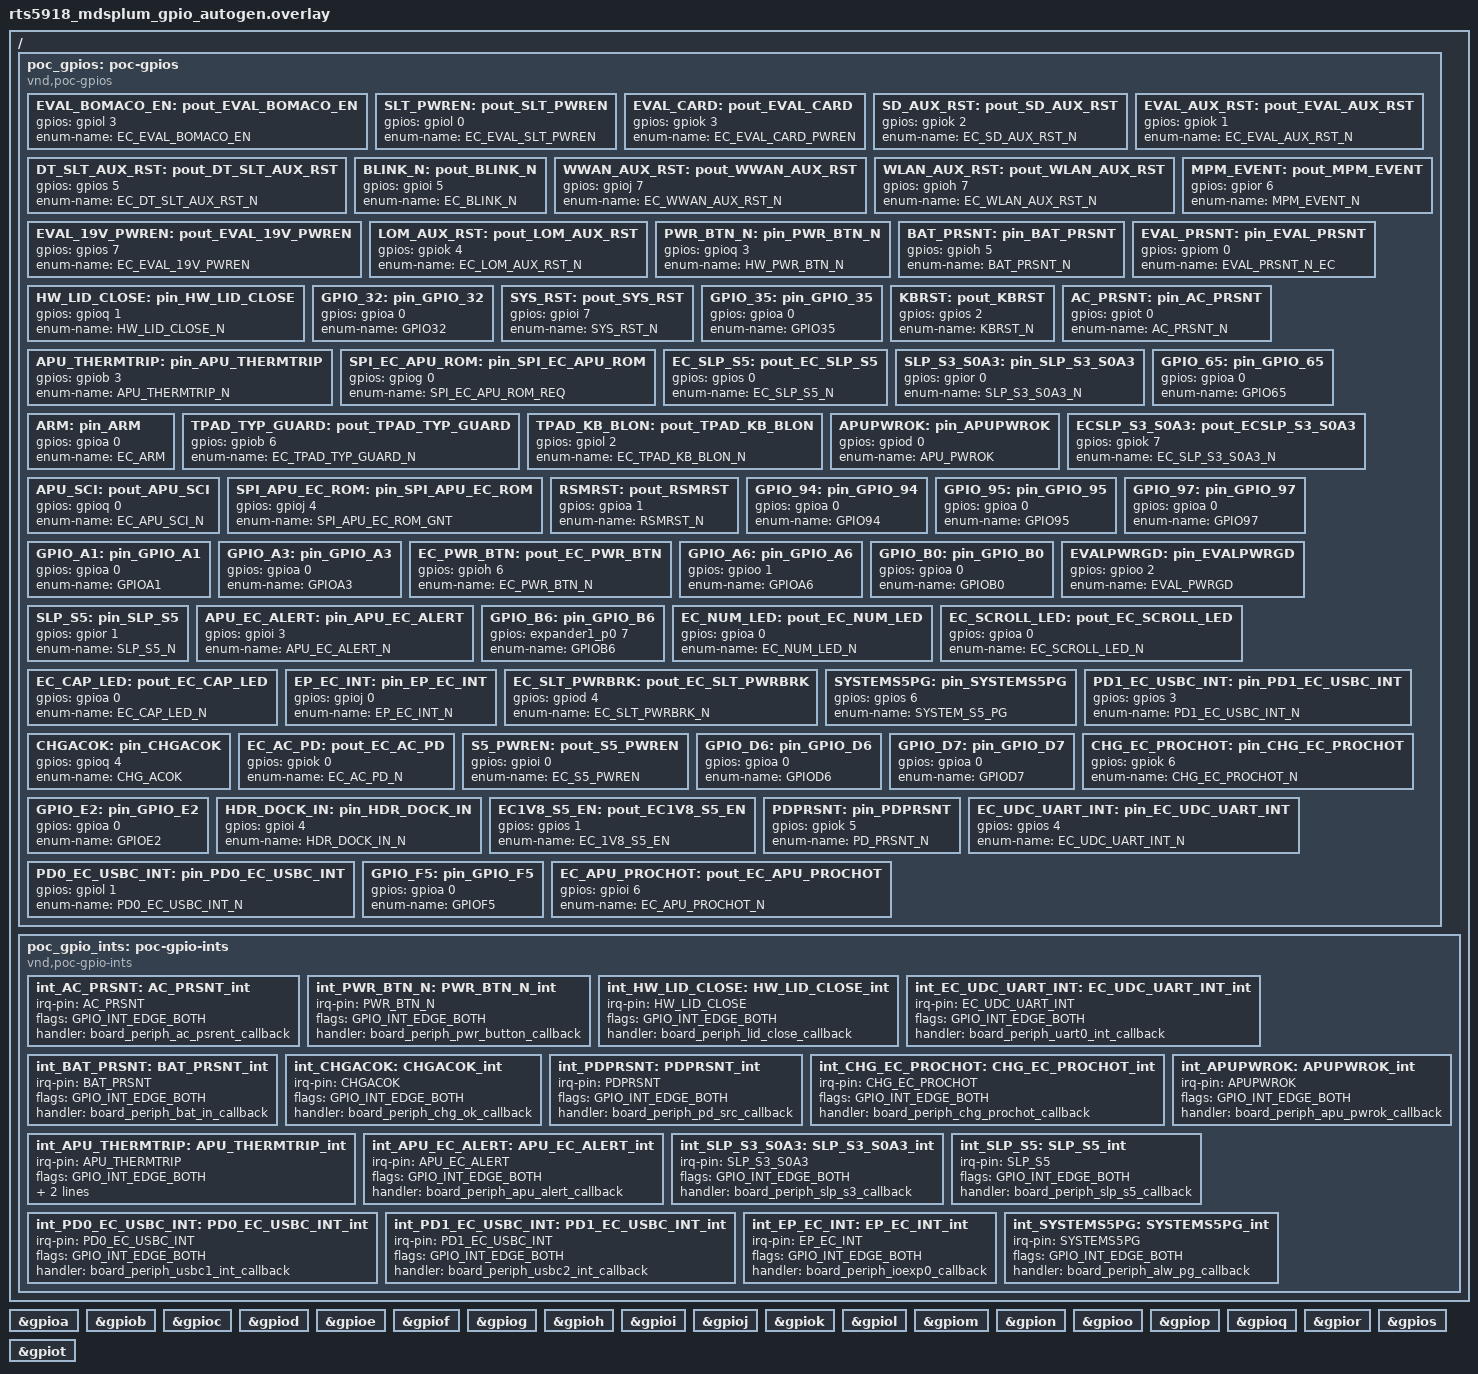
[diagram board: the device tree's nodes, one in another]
/*
 * SPDX-License-Identifier: Apache-2.0
 *
 * Copyright (c) 2026 Realtek Semiconductor Corporation, SIBG-SD7
 *
 * TODO(realtek-schematic): THIS FILE IS A BISON-LEGACY COPY.
 *
 * Every `gpios = <&gpio<bank> <pin> ...>` entry below was generated
 * from the Lenovo Bison schematic. The pad numbers are NOT correct
 * for AMD MDS Plum yet — they will need to be regenerated from a
 * Plum-specific BGA→net→pin spreadsheet once available.
 *
 * Until then the build still compiles because gpioa..gpiop are all
 * marked `status = "okay"`, but any runtime gpio_pin_set call against
 * an EC_GPIO_xx token will toggle the wrong physical pin. Do not
 * power up real Plum hardware with this overlay verbatim.
 *
 * Regeneration recipe (once Plum_pindef.xlsx exists):
 *   1. Copy boards/nuvoton/npcx4mnx_mdsplum/Plum_main.csv to
 *      gpio/plum_gpio.xlsx with columns: BGA, Net, RTS5918_Function.
 *   2. Run: python scripts/gen_poc_from_xlsx.py
 *      (port from lenovo_p/ecfw-zephyr/scripts/gen_poc_from_xlsx.py)
 *   3. Overwrite this file with the output.
 *
 * AUTO-GENERATED by scripts/gen_poc_from_xlsx.py from:
 *   ../gpio/GPIO_copy.dtsi   -- template: structure, order, labels, comments
 *   ../gpio/bison_gpio.xlsx  -- data: BGA_NET_CODE + rts5918_pin_function
 *                               joined on BGA -> (Code, Net, Function)
 *
 * Transformations applied vs. the source dtsi:
 *   * compatible renamed to the Realtek "vnd,poc-gpios" /
 *     "vnd,poc-gpio-ints" bindings.
 *   * &{/def-io-conf-list} pinmux block removed -- Realtek uses
 *     realtek/ec/rts5918-pinctrl.dtsi, wired up in rts5918_bison.dts.
 *   * eSPI VWire children rewritten: the Nuvoton-specific &msvw0x /
 *     &smvw0x phandles are replaced with &gpioa 0 because RTS5918 has
 *     no msvw/smvw devicetree nodes, but the GPIO_VWIRE flag is kept
 *     so the encoded enum value carries BIT(20) and IoPort.c (line
 *     ~441/584) routes IoSet/IoClr/IoGet calls via the eSPI VW
 *     dispatcher. Each entry in the xlsx `vwire_signals` sheet that
 *     the template doesn't already include is appended automatically.
 *   * `gpios = <&gpio<N> <pin> ...>` rewritten to
 *     `gpios = <&gpio<a..t> <pin%8> ...>` using linear GPIO# =
 *     bank*8+pin (verified from RTS5918.h IRQ comments).
 *   * Nuvoton flag tokens (GPIO_OUTPUT_HIGH / GPIO_OUTPUT_LOW /
 *     GPIO_DEFINE) preserved verbatim -- all are defined in
 *     include/dt-bindings/gpio_defines.h and expand to the expected
 *     bit pattern after the devicetree preprocessor runs.
 *   * GPIO_DEFINE stripped only when that row is falling through to a
 *     GPIO_UNDEFINE_PIN stub (the two are opposites).
 *   * Interrupt children with GPIO_INT_DISABLE flags dropped
 *     (Realtek binding does not accept the disabled variant).
 *   * Template rows without a real BGA mapping that are not eSPI
 *     vwire signals are emitted as GPIO_UNDEFINE_PIN stubs (encoded
 *     enum carries BIT(30) so middle/gpio/mdl_gpio_hub.c safety net
 *     returns -ENODEV at runtime). The PInGpio<NNN> generic-name family
 *     (PInGpio001 / PInGpio0H4 / PInGpioSBY01...) is the lone
 *     exception: it is dropped entirely; syspower.c
 *     IoPortToBeUnpoweredInMOff[] drops these entries so source links.
 *   * A source-grep backfill walks Jupiter / middle / include / app /
 *     common / drivers for any PIn-prefixed or POut-prefixed identifier
 *     referenced but not present in the dtsi template, and emits them
 *     as GPIO_UNDEFINE_PIN stubs too (still excluding PInGpio<NNN>).
 *
 * Do not hand-edit; regenerate with:
 *     python scripts/gen_poc_from_xlsx.py
 */

#include <zephyr/dt-bindings/gpio/gpio.h>
#include <zephyr/dt-bindings/gpio/realtek-gpio.h>
#include <dt-bindings/gpio_defines.h>

&gpioa { status = "okay"; };
&gpiob { status = "okay"; };
&gpioc { status = "okay"; };
&gpiod { status = "okay"; };
&gpioe { status = "okay"; };
&gpiof { status = "okay"; };
&gpiog { status = "okay"; };
&gpioh { status = "okay"; };
&gpioi { status = "okay"; };
&gpioj { status = "okay"; };
&gpiok { status = "okay"; };
&gpiol { status = "okay"; };
&gpiom { status = "okay"; };
&gpion { status = "okay"; };
&gpioo { status = "okay"; };
&gpiop { status = "okay"; };
&gpioq { status = "okay"; };
&gpior { status = "okay"; };
&gpios { status = "okay"; };
&gpiot { status = "okay"; };

/ {
	poc_gpios: poc-gpios {
		compatible = "vnd,poc-gpios";

		// it have to be declared most front if the pin is not used.
		// GPIO091
		EVAL_BOMACO_EN: pout_EVAL_BOMACO_EN {
			gpios = <&gpiol 3 (GPIO_ACTIVE_HIGH | GPIO_INPUT | GPIO_DEFINE)>;
			enum-name = "EC_EVAL_BOMACO_EN";
		};
		// GPIO088
		SLT_PWREN: pout_SLT_PWREN {
			gpios = <&gpiol 0 (GPIO_ACTIVE_HIGH | GPIO_INPUT | GPIO_DEFINE)>;
			enum-name = "EC_EVAL_SLT_PWREN";
		};
		// GPIO083
		EVAL_CARD: pout_EVAL_CARD {
			gpios = <&gpiok 3 (GPIO_ACTIVE_HIGH | GPIO_INPUT | GPIO_DEFINE)>;
			enum-name = "EC_EVAL_CARD_PWREN";
		};
		// GPIO082
		SD_AUX_RST: pout_SD_AUX_RST {
			gpios = <&gpiok 2 (GPIO_ACTIVE_HIGH | GPIO_INPUT | GPIO_DEFINE)>;
			enum-name = "EC_SD_AUX_RST_N";
		};
		// GPIO081
		EVAL_AUX_RST: pout_EVAL_AUX_RST {
			gpios = <&gpiok 1 (GPIO_ACTIVE_HIGH | GPIO_INPUT | GPIO_DEFINE)>;
			enum-name = "EC_EVAL_AUX_RST_N";
		};
		// GPIO149
		DT_SLT_AUX_RST: pout_DT_SLT_AUX_RST {
			gpios = <&gpios 5 (GPIO_ACTIVE_HIGH | GPIO_INPUT | GPIO_DEFINE)>;
			enum-name = "EC_DT_SLT_AUX_RST_N";
		};
		// GPIO069
		BLINK_N: pout_BLINK_N {
			gpios = <&gpioi 5 (GPIO_ACTIVE_HIGH | GPIO_OUTPUT_HIGH | GPIO_OPEN_DRAIN | GPIO_DEFINE)>;
			enum-name = "EC_BLINK_N";
		};
		// GPIO079
		WWAN_AUX_RST: pout_WWAN_AUX_RST {
			gpios = <&gpioj 7 (GPIO_ACTIVE_HIGH | GPIO_INPUT | GPIO_DEFINE)>;
			enum-name = "EC_WWAN_AUX_RST_N";
		};
		// GPIO063
		WLAN_AUX_RST: pout_WLAN_AUX_RST {
			gpios = <&gpioh 7 (GPIO_ACTIVE_HIGH | GPIO_INPUT | GPIO_DEFINE)>;
			enum-name = "EC_WLAN_AUX_RST_N";
		};
		// GPIO142
		MPM_EVENT: pout_MPM_EVENT {
			gpios = <&gpior 6 (GPIO_ACTIVE_HIGH | GPIO_INPUT | GPIO_DEFINE)>;
			enum-name = "MPM_EVENT_N";
		};
		// GPIO151
		EVAL_19V_PWREN: pout_EVAL_19V_PWREN {
			gpios = <&gpios 7 (GPIO_ACTIVE_HIGH | GPIO_INPUT | GPIO_DEFINE)>;
			enum-name = "EC_EVAL_19V_PWREN";
		};
		// GPIO084
		LOM_AUX_RST: pout_LOM_AUX_RST {
			gpios = <&gpiok 4 (GPIO_ACTIVE_HIGH | GPIO_INPUT | GPIO_DEFINE)>;
			enum-name = "EC_LOM_AUX_RST_N";
		};
		// GPIO131
		PWR_BTN_N: pin_PWR_BTN_N {
			gpios = <&gpioq 3 (GPIO_ACTIVE_HIGH | GPIO_INPUT | GPIO_DEFINE)>;
			enum-name = "HW_PWR_BTN_N";
		};
		// GPIO061
		BAT_PRSNT: pin_BAT_PRSNT {
			gpios = <&gpioh 5 (GPIO_ACTIVE_HIGH | GPIO_INPUT | GPIO_DEFINE)>;
			enum-name = "BAT_PRSNT_N";
		};
		// GPIO096
		EVAL_PRSNT: pin_EVAL_PRSNT {
			gpios = <&gpiom 0 (GPIO_ACTIVE_HIGH | GPIO_INPUT | GPIO_DEFINE)>;
			enum-name = "EVAL_PRSNT_N_EC";
		};
		// GPIO129
		HW_LID_CLOSE: pin_HW_LID_CLOSE {
			gpios = <&gpioq 1 (GPIO_ACTIVE_HIGH | GPIO_INPUT | GPIO_DEFINE)>;
			enum-name = "HW_LID_CLOSE_N";
		};
		GPIO_32: pin_GPIO_32 {
			gpios = <&gpioa 0 (GPIO_ACTIVE_HIGH | GPIO_INPUT | GPIO_UNDEFINE_PIN)>;
			enum-name = "GPIO32";
		};
		// GPIO071
		SYS_RST: pout_SYS_RST {
			gpios = <&gpioi 7 (GPIO_ACTIVE_HIGH | GPIO_OUTPUT_HIGH | GPIO_DEFINE)>;
			enum-name = "SYS_RST_N";
		};
		GPIO_35: pin_GPIO_35 {
			gpios = <&gpioa 0 (GPIO_ACTIVE_HIGH | GPIO_INPUT | GPIO_UNDEFINE_PIN)>;
			enum-name = "GPIO35";
		};
		// GPIO146
		KBRST: pout_KBRST {
			gpios = <&gpios 2 (GPIO_ACTIVE_HIGH | GPIO_OUTPUT_HIGH | GPIO_OPEN_DRAIN | GPIO_DEFINE)>;
			enum-name = "KBRST_N";
		};
		// GPIO152
		AC_PRSNT: pin_AC_PRSNT {
			gpios = <&gpiot 0 (GPIO_ACTIVE_HIGH | GPIO_INPUT | GPIO_DEFINE)>;
			enum-name = "AC_PRSNT_N";
		};
		// GPIO011
		APU_THERMTRIP: pin_APU_THERMTRIP {
			gpios = <&gpiob 3 (GPIO_ACTIVE_HIGH | GPIO_INPUT | GPIO_DEFINE)>;
			enum-name = "APU_THERMTRIP_N";
		};
		// GPIO048
		SPI_EC_APU_ROM: pin_SPI_EC_APU_ROM {
			gpios = <&gpiog 0 (GPIO_ACTIVE_HIGH | GPIO_INPUT | GPIO_DEFINE)>;
			enum-name = "SPI_EC_APU_ROM_REQ";
		};
		// GPIO144
		EC_SLP_S5: pout_EC_SLP_S5 {
			gpios = <&gpios 0 (GPIO_ACTIVE_HIGH | GPIO_OUTPUT_LOW | GPIO_DEFINE)>;
			enum-name = "EC_SLP_S5_N";
		};
		// GPIO136
		SLP_S3_S0A3: pin_SLP_S3_S0A3 {
			gpios = <&gpior 0 (GPIO_ACTIVE_HIGH | GPIO_INPUT | GPIO_DEFINE)>;
			enum-name = "SLP_S3_S0A3_N";
		};
		GPIO_65: pin_GPIO_65 {
			gpios = <&gpioa 0 (GPIO_ACTIVE_HIGH | GPIO_INPUT | GPIO_UNDEFINE_PIN)>;
			enum-name = "GPIO65";
		};
		ARM: pin_ARM {
			gpios = <&gpioa 0 (GPIO_ACTIVE_HIGH | GPIO_INPUT | GPIO_UNDEFINE_PIN)>;
			enum-name = "EC_ARM";
		};
		// GPIO014
		TPAD_TYP_GUARD: pout_TPAD_TYP_GUARD {
			gpios = <&gpiob 6 (GPIO_ACTIVE_HIGH | GPIO_OUTPUT_HIGH | GPIO_OPEN_DRAIN | GPIO_DEFINE)>;
			enum-name = "EC_TPAD_TYP_GUARD_N";
		};
		// GPIO090
		TPAD_KB_BLON: pout_TPAD_KB_BLON {
			gpios = <&gpiol 2 (GPIO_ACTIVE_HIGH | GPIO_OUTPUT_HIGH | GPIO_OPEN_DRAIN | GPIO_DEFINE)>;
			enum-name = "EC_TPAD_KB_BLON_N";
		};
		// GPIO024
		APUPWROK: pin_APUPWROK {
			gpios = <&gpiod 0 (GPIO_ACTIVE_HIGH | GPIO_INPUT | GPIO_DEFINE)>;
			enum-name = "APU_PWROK";
		};
		// GPIO087
		ECSLP_S3_S0A3: pout_ECSLP_S3_S0A3 {
			gpios = <&gpiok 7 (GPIO_ACTIVE_HIGH | GPIO_OUTPUT_LOW | GPIO_DEFINE)>;
			enum-name = "EC_SLP_S3_S0A3_N";
		};
		// GPIO128
		APU_SCI: pout_APU_SCI {
			gpios = <&gpioq 0 (GPIO_ACTIVE_HIGH | GPIO_OUTPUT_HIGH | GPIO_OPEN_DRAIN | GPIO_DEFINE)>;
			enum-name = "EC_APU_SCI_N";
		};
		// GPIO076
		SPI_APU_EC_ROM: pin_SPI_APU_EC_ROM {
			gpios = <&gpioj 4 (GPIO_ACTIVE_HIGH | GPIO_INPUT | GPIO_DEFINE)>;
			enum-name = "SPI_APU_EC_ROM_GNT";
		};
		// GPIO001
		RSMRST: pout_RSMRST {
			gpios = <&gpioa 1 (GPIO_ACTIVE_HIGH | GPIO_OUTPUT_LOW | GPIO_DEFINE)>;
			enum-name = "RSMRST_N";
		};
		GPIO_94: pin_GPIO_94 {
			gpios = <&gpioa 0 (GPIO_ACTIVE_HIGH | GPIO_INPUT | GPIO_UNDEFINE_PIN)>;
			enum-name = "GPIO94";
		};
		GPIO_95: pin_GPIO_95 {
			gpios = <&gpioa 0 (GPIO_ACTIVE_HIGH | GPIO_INPUT | GPIO_UNDEFINE_PIN)>;
			enum-name = "GPIO95";
		};
		GPIO_97: pin_GPIO_97 {
			gpios = <&gpioa 0 (GPIO_ACTIVE_HIGH | GPIO_INPUT | GPIO_UNDEFINE_PIN)>;
			enum-name = "GPIO97";
		};
		GPIO_A1: pin_GPIO_A1 {
			gpios = <&gpioa 0 (GPIO_ACTIVE_HIGH | GPIO_INPUT | GPIO_UNDEFINE_PIN)>;
			enum-name = "GPIOA1";
		};
		GPIO_A3: pin_GPIO_A3 {
			gpios = <&gpioa 0 (GPIO_ACTIVE_HIGH | GPIO_INPUT | GPIO_UNDEFINE_PIN)>;
			enum-name = "GPIOA3";
		};
		// GPIO062
		EC_PWR_BTN: pout_EC_PWR_BTN {
			gpios = <&gpioh 6 (GPIO_ACTIVE_HIGH | GPIO_OUTPUT_HIGH | GPIO_OPEN_DRAIN | GPIO_DEFINE)>;
			enum-name = "EC_PWR_BTN_N";
		};
		GPIO_A6: pin_GPIO_A6 {
			gpios = <&gpioo 1 (GPIO_ACTIVE_HIGH | GPIO_INPUT | GPIO_UNDEFINE_PIN)>;
			enum-name = "GPIOA6";
		};
		GPIO_B0: pin_GPIO_B0 {
			gpios = <&gpioa 0 (GPIO_ACTIVE_HIGH | GPIO_INPUT | GPIO_UNDEFINE_PIN)>;
			enum-name = "GPIOB0";
		};
		// GPIO114
		EVALPWRGD: pin_EVALPWRGD {
			gpios = <&gpioo 2 (GPIO_ACTIVE_HIGH | GPIO_INPUT | GPIO_DEFINE)>;
			enum-name = "EVAL_PWRGD";
		};
		// GPIO137
		SLP_S5: pin_SLP_S5 {
			gpios = <&gpior 1 (GPIO_ACTIVE_HIGH | GPIO_INPUT | GPIO_DEFINE)>;
			enum-name = "SLP_S5_N";
		};
		// GPIO067
		APU_EC_ALERT: pin_APU_EC_ALERT {
			gpios = <&gpioi 3 (GPIO_ACTIVE_HIGH | GPIO_INPUT | GPIO_DEFINE)>;
			enum-name = "APU_EC_ALERT_N";
		};
		GPIO_B6: pin_GPIO_B6 {
			gpios = <&expander1_p0 7 (GPIO_ACTIVE_HIGH | GPIO_INPUT | GPIO_UNDEFINE_PIN)>;
			enum-name = "GPIOB6";
		};
		EC_NUM_LED: pout_EC_NUM_LED {
			gpios = <&gpioa 0 (GPIO_ACTIVE_HIGH | GPIO_OUTPUT_HIGH | GPIO_OPEN_DRAIN | GPIO_UNDEFINE_PIN)>;
			enum-name = "EC_NUM_LED_N";
		};
		EC_SCROLL_LED: pout_EC_SCROLL_LED {
			gpios = <&gpioa 0 (GPIO_ACTIVE_HIGH | GPIO_OUTPUT_HIGH | GPIO_OPEN_DRAIN | GPIO_UNDEFINE_PIN)>;
			enum-name = "EC_SCROLL_LED_N";
		};
		EC_CAP_LED: pout_EC_CAP_LED {
			gpios = <&gpioa 0 (GPIO_ACTIVE_HIGH | GPIO_OUTPUT_LOW | GPIO_OPEN_DRAIN | GPIO_UNDEFINE_PIN)>;
			enum-name = "EC_CAP_LED_N";
		};
		// GPIO072
		EP_EC_INT: pin_EP_EC_INT {
			gpios = <&gpioj 0 (GPIO_ACTIVE_HIGH | GPIO_INPUT | GPIO_DEFINE)>;
			enum-name = "EP_EC_INT_N";
		};
		// GPIO028
		EC_SLT_PWRBRK: pout_EC_SLT_PWRBRK {
			gpios = <&gpiod 4 (GPIO_ACTIVE_HIGH | GPIO_OUTPUT_HIGH | GPIO_OPEN_DRAIN | GPIO_DEFINE)>;
			enum-name = "EC_SLT_PWRBRK_N";
		};
		// GPIO150
		SYSTEMS5PG: pin_SYSTEMS5PG {
			gpios = <&gpios 6 (GPIO_ACTIVE_HIGH | GPIO_INPUT | GPIO_DEFINE)>;
			enum-name = "SYSTEM_S5_PG";
		};
		// GPIO147
		PD1_EC_USBC_INT: pin_PD1_EC_USBC_INT {
			gpios = <&gpios 3 (GPIO_ACTIVE_HIGH | GPIO_INPUT | GPIO_DEFINE)>;
			enum-name = "PD1_EC_USBC_INT_N";
		};
		// GPIO132
		CHGACOK: pin_CHGACOK {
			gpios = <&gpioq 4 (GPIO_ACTIVE_HIGH | GPIO_INPUT | GPIO_DEFINE)>;
			enum-name = "CHG_ACOK";
		};
		// GPIO080
		EC_AC_PD: pout_EC_AC_PD {
			gpios = <&gpiok 0 (GPIO_ACTIVE_HIGH | GPIO_OUTPUT_LOW | GPIO_DEFINE)>;
			enum-name = "EC_AC_PD_N";
		};
		// GPIO064
		S5_PWREN: pout_S5_PWREN {
			gpios = <&gpioi 0 (GPIO_ACTIVE_HIGH | GPIO_OUTPUT_LOW | GPIO_DEFINE)>;
			enum-name = "EC_S5_PWREN";
		};
		GPIO_D6: pin_GPIO_D6 {
			gpios = <&gpioa 0 (GPIO_ACTIVE_HIGH | GPIO_INPUT | GPIO_UNDEFINE_PIN)>;
			enum-name = "GPIOD6";
		};
		GPIO_D7: pin_GPIO_D7 {
			gpios = <&gpioa 0 (GPIO_ACTIVE_HIGH | GPIO_INPUT | GPIO_UNDEFINE_PIN)>;
			enum-name = "GPIOD7";
		};
		// GPIO086
		CHG_EC_PROCHOT: pin_CHG_EC_PROCHOT {
			gpios = <&gpiok 6 (GPIO_ACTIVE_HIGH | GPIO_INPUT | GPIO_DEFINE)>;
			enum-name = "CHG_EC_PROCHOT_N";
		};
		GPIO_E2: pin_GPIO_E2 {
			gpios = <&gpioa 0 (GPIO_ACTIVE_HIGH | GPIO_INPUT | GPIO_UNDEFINE_PIN)>;
			enum-name = "GPIOE2";
		};
		// GPIO068
		HDR_DOCK_IN: pin_HDR_DOCK_IN {
			gpios = <&gpioi 4 (GPIO_ACTIVE_HIGH | GPIO_INPUT | GPIO_DEFINE)>;
			enum-name = "HDR_DOCK_IN_N";
		};
		// GPIO145
		EC1V8_S5_EN: pout_EC1V8_S5_EN {
			gpios = <&gpios 1 (GPIO_ACTIVE_HIGH | GPIO_OUTPUT_HIGH | GPIO_DEFINE)>;
			enum-name = "EC_1V8_S5_EN";
		};
		// GPIO085
		PDPRSNT: pin_PDPRSNT {
			gpios = <&gpiok 5 (GPIO_ACTIVE_HIGH | GPIO_INPUT | GPIO_DEFINE)>;
			enum-name = "PD_PRSNT_N";
		};
		// GPIO148
		EC_UDC_UART_INT: pin_EC_UDC_UART_INT {
			gpios = <&gpios 4 (GPIO_ACTIVE_HIGH | GPIO_INPUT | GPIO_DEFINE)>;
			enum-name = "EC_UDC_UART_INT_N";
		};
		// GPIO089
		PD0_EC_USBC_INT: pin_PD0_EC_USBC_INT {
			gpios = <&gpiol 1 (GPIO_ACTIVE_HIGH | GPIO_INPUT | GPIO_DEFINE)>;
			enum-name = "PD0_EC_USBC_INT_N";
		};
		GPIO_F5: pin_GPIO_F5 {
			gpios = <&gpioa 0 (GPIO_ACTIVE_HIGH | GPIO_INPUT | GPIO_UNDEFINE_PIN)>;
			enum-name = "GPIOF5";
		};
		// GPIO070
		EC_APU_PROCHOT: pout_EC_APU_PROCHOT {
			gpios = <&gpioi 6 (GPIO_ACTIVE_HIGH | GPIO_OUTPUT_HIGH | GPIO_OPEN_DRAIN | GPIO_DEFINE)>;
			enum-name = "EC_APU_PROCHOT_N";
		};
	};

	poc_gpio_ints: poc-gpio-ints {
		compatible = "vnd,poc-gpio-ints";

		int_AC_PRSNT: AC_PRSNT_int {
			irq-pin = <&AC_PRSNT>;
			flags = <GPIO_INT_EDGE_BOTH>;
			handler = "board_periph_ac_psrent_callback";
		};
		
		int_PWR_BTN_N: PWR_BTN_N_int {
			irq-pin = <&PWR_BTN_N>;
			flags = <GPIO_INT_EDGE_BOTH>;
			handler = "board_periph_pwr_button_callback";
		};
		/*
		int_HDR_DOCK_IN: HDR_DOCK_IN_int {
			irq-pin = <&HDR_DOCK_IN>;
			flags = <GPIO_INT_EDGE_BOTH>;
			handler = "board_periph_dock_in_callback";
		};
		*/
		int_HW_LID_CLOSE: HW_LID_CLOSE_int {
			irq-pin = <&HW_LID_CLOSE>;
			flags = <GPIO_INT_EDGE_BOTH>;
			handler = "board_periph_lid_close_callback";
		};
		
		int_EC_UDC_UART_INT: EC_UDC_UART_INT_int {
			irq-pin = <&EC_UDC_UART_INT>;
			flags = <GPIO_INT_EDGE_BOTH>;
			handler = "board_periph_uart0_int_callback";
		};		

		int_BAT_PRSNT: BAT_PRSNT_int {
			irq-pin = <&BAT_PRSNT>;
			flags = <GPIO_INT_EDGE_BOTH>;
			handler = "board_periph_bat_in_callback";
		};
		
		int_CHGACOK: CHGACOK_int {
			irq-pin = <&CHGACOK>;
			flags = <GPIO_INT_EDGE_BOTH>;
			handler = "board_periph_chg_ok_callback";
		};			

		int_PDPRSNT: PDPRSNT_int {
			irq-pin = <&PDPRSNT>;
			flags = <GPIO_INT_EDGE_BOTH>;
			handler = "board_periph_pd_src_callback";
		};
		
		int_CHG_EC_PROCHOT: CHG_EC_PROCHOT_int {
			irq-pin = <&CHG_EC_PROCHOT>;
			flags = <GPIO_INT_EDGE_BOTH>;
			handler = "board_periph_chg_prochot_callback";
		};					

		int_APUPWROK: APUPWROK_int {
			irq-pin = <&APUPWROK>;
			flags = <GPIO_INT_EDGE_BOTH>;
			handler = "board_periph_apu_pwrok_callback";
		};			

		int_APU_THERMTRIP: APU_THERMTRIP_int {
			irq-pin = <&APU_THERMTRIP>;
			flags = <GPIO_INT_EDGE_BOTH>;
			handler = "board_periph_apu_thermal_trip_callback";
		};
		
		int_APU_EC_ALERT: APU_EC_ALERT_int {
			irq-pin = <&APU_EC_ALERT>;
			flags = <GPIO_INT_EDGE_BOTH>;
			handler = "board_periph_apu_alert_callback";
		};			

		int_SLP_S3_S0A3: SLP_S3_S0A3_int {
			irq-pin = <&SLP_S3_S0A3>;
			flags = <GPIO_INT_EDGE_BOTH>;
			handler = "board_periph_slp_s3_callback";
		};			

		int_SLP_S5: SLP_S5_int {
			irq-pin = <&SLP_S5>;
			flags = <GPIO_INT_EDGE_BOTH>;
			handler = "board_periph_slp_s5_callback";
		};
		
		int_PD0_EC_USBC_INT: PD0_EC_USBC_INT_int {
			irq-pin = <&PD0_EC_USBC_INT>;
			flags = <GPIO_INT_EDGE_BOTH>;
			handler = "board_periph_usbc1_int_callback";
		};				

		int_PD1_EC_USBC_INT: PD1_EC_USBC_INT_int {
			irq-pin = <&PD1_EC_USBC_INT>;
			flags = <GPIO_INT_EDGE_BOTH>;
			handler = "board_periph_usbc2_int_callback";
		};
		
		int_EP_EC_INT: EP_EC_INT_int {
			irq-pin = <&EP_EC_INT>;
			flags = <GPIO_INT_EDGE_BOTH>;
			handler = "board_periph_ioexp0_callback";
		};		

		int_SYSTEMS5PG: SYSTEMS5PG_int {
			irq-pin = <&SYSTEMS5PG>;
			flags = <GPIO_INT_EDGE_BOTH>;
			handler = "board_periph_alw_pg_callback";
		};						
		//
		//
		//
	};
};
